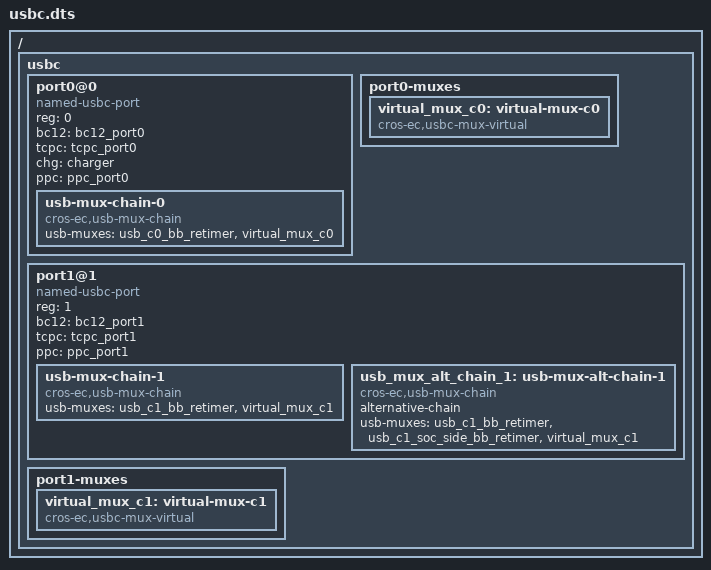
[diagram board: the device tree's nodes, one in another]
/* Copyright 2022 The ChromiumOS Authors
 * Use of this source code is governed by a BSD-style license that can be
 * found in the LICENSE file.
 */

/ {
	usbc {
		#address-cells = <1>;
		#size-cells = <0>;

		port0@0 {
			compatible = "named-usbc-port";
			reg = <0>;
			bc12 = <&bc12_port0>;
			tcpc = <&tcpc_port0>;
			chg = <&charger>;
			usb-mux-chain-0 {
				compatible = "cros-ec,usb-mux-chain";
				usb-muxes = <&usb_c0_bb_retimer
					     &virtual_mux_c0>;
			};
			ppc = <&ppc_port0>;
		};
		port0-muxes {
			virtual_mux_c0: virtual-mux-c0 {
				compatible = "cros-ec,usbc-mux-virtual";
			};
		};

		port1@1 {
			compatible = "named-usbc-port";
			reg = <1>;
			bc12 = <&bc12_port1>;
			tcpc = <&tcpc_port1>;
			usb-mux-chain-1 {
				compatible = "cros-ec,usb-mux-chain";
				usb-muxes = <&usb_c1_bb_retimer
					     &virtual_mux_c1>;
			};
			usb_mux_alt_chain_1: usb-mux-alt-chain-1 {
				compatible = "cros-ec,usb-mux-chain";
				alternative-chain;
				usb-muxes = <&usb_c1_bb_retimer
					     &usb_c1_soc_side_bb_retimer
					     &virtual_mux_c1>;
			};
			ppc = <&ppc_port1>;
		};
		port1-muxes {
			virtual_mux_c1: virtual-mux-c1 {
				compatible = "cros-ec,usbc-mux-virtual";
			};
		};
	};
};
